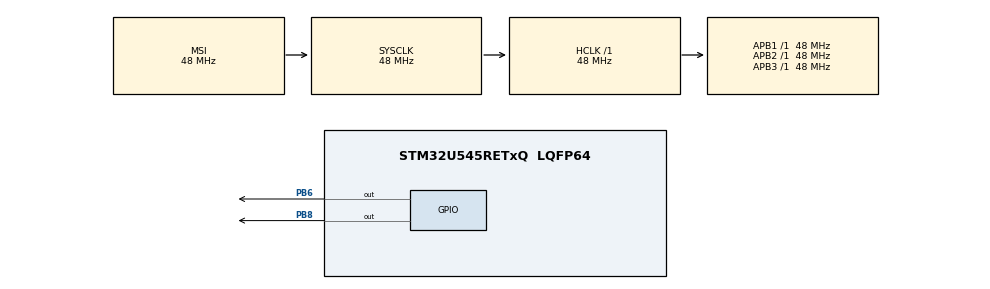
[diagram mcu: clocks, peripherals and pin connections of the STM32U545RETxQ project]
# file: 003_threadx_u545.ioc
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CORTEX_M33_NS.userName=CORTEX_M33
Mcu.Family=STM32U5
Mcu.Name=STM32U545RETxQ
Mcu.Package=LQFP64
NVIC.IWDG_IRQn=true\:0\:0\:false\:false\:true\:false\:true\:true\:true
NVIC.LPTIM1_IRQn=true\:0\:0\:false\:false\:true\:false\:true\:true\:true
NVIC.PriorityGroup=NVIC_PRIORITYGROUP_4
NVIC.RTC_IRQn=true\:0\:0\:false\:false\:true\:false\:true\:true\:true
NVIC.TIM1_UP_IRQn=true\:15\:0\:false\:false\:true\:false\:false\:true\:true
NVIC.TIM4_IRQn=true\:0\:0\:false\:false\:true\:false\:true\:true\:true
NVIC.TimeBase=TIM1_UP_IRQn
NVIC.TimeBaseIP=TIM1
PB6.Signal=GPIO_Output
PB8.Signal=GPIO_Output
PC14-OSC32_IN\ (PC14).Mode=LSE-External-Oscillator
PC14-OSC32_IN\ (PC14).Signal=RCC_OSC32_IN
PC15-OSC32_OUT\ (PC15).Mode=LSE-External-Oscillator
PC15-OSC32_OUT\ (PC15).Signal=RCC_OSC32_OUT
PWR.PowerMode=PWR_SMPS_SUPPLY
ProjectManager.HeapSize=0x200
ProjectManager.StackSize=0x400
ProjectManager.TargetToolchain=STM32CubeIDE
RCC.ADCFreq_Value=16000000
RCC.AHBFreq_Value=48000000
RCC.APB1Freq_Value=48000000
RCC.APB1TimFreq_Value=48000000
RCC.APB2Freq_Value=48000000
RCC.APB2TimFreq_Value=48000000
RCC.APB3Freq_Value=48000000
RCC.CortexFreq_Value=48000000
RCC.DACCLockSelectionVirtualString=RCC_DAC1CLKSOURCE_LSI
RCC.EPOD_VALUE=48000000
RCC.HCLKFreq_Value=48000000
RCC.HSE_VALUE=16000000
RCC.HSI48_VALUE=48000000
RCC.HSI_VALUE=16000000
RCC.LSIDIV_VALUE=32000
RCC.MSIClockRange=RCC_MSIRANGE_0
RCC.MSI_VALUE=48000000
RCC.SYSCLKFreq_VALUE=48000000
RCC.USBFreq_Value=48000000
RCC.VCOOutputFreq_Value=6192000000
THREADX.TX_APP_CREATION=1
THREADX.TX_APP_GENERATE_INIT_CODE=true
THREADX.TX_APP_MEM_POOL_SIZE=8192
THREADX.TX_APP_MSG_QUEUE_CREATION=1
THREADX.TX_APP_MUTEX_CREATION=1
THREADX.TX_APP_SEM_CREATION=1
THREADX.TX_APP_STACK_SIZE=4096
THREADX.TX_LOW_POWER=1
THREADX.TX_MINIMUM_STACK=200
THREADX.TX_TIMER_THREAD_STACK_SIZE=4096
VP_ICACHE_VS_ICACHE.Mode=DirectMappedCache
VP_IWDG_VS_IWDG.Mode=IWDG_Activate
VP_LPBAMQUEUE_VS_QUEUE.Mode=QUEUEMODE
VP_LPBAM_VS_SIG1.Mode=SmartRun
VP_LPBAM_VS_SIG4.Mode=LPDMA1
VP_LPTIM1_VS_LPTIM_counterModeInternalClock.Mode=Counts__internal_clock_event_00
VP_MEMORYMAP_VS_MEMORYMAP.Mode=CurAppReg
VP_PWR_VS_LPOM.Mode=PowerOptimisation
VP_PWR_VS_SECSignals.Mode=Security/Privilege
VP_RTC_VS_RTC_Activate.Mode=RTC_Enabled
VP_RTC_VS_RTC_Calendar.Mode=RTC_Calendar
VP_RTC_VS_RTC_WakeUp_intern.Mode=WakeUp
VP_SYS_VS_tim1.Mode=TIM1
VP_THREADX_VS_RTOSJjThreadXJjCoreJjDefault.Mode=Core_Default
VP_THREADX_VS_RTOSJjThreadXJjLow_Power_Support.Mode=Low_Power_Support
VP_THREADX_VS_RTOSJjThreadXJjPerformance_InfoJjDefault.Mode=Performance_Default
VP_TIM4_VS_ClockSourceINT.Mode=Internal
board=custom

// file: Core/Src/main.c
/* USER CODE BEGIN Header */
/**
  ******************************************************************************
  * @file           : main.c
  * @brief          : Main program body
  ******************************************************************************
  * @attention
  *
  * Copyright (c) 2025 STMicroelectronics.
  * All rights reserved.
  *
  * This software is licensed under terms that can be found in the LICENSE file
  * in the root directory of this software component.
  * If no LICENSE file comes with this software, it is provided AS-IS.
  *
  ******************************************************************************
  */
/* USER CODE END Header */
#include "app_threadx.h"
#include "main.h"
#include "icache.h"
#include "iwdg.h"
#include "lptim.h"
#include "rtc.h"
#include "tim.h"
#include "gpio.h"

/* USER CODE BEGIN Includes */
#include "SEGGER_RTT.h"
/* USER CODE END Includes */

void SystemClock_Config(void);
static void SystemPower_Config(void);

int main(void)
{

  /* USER CODE BEGIN 1 */
  /* Initialize RTT early for debugging */
  SEGGER_RTT_Init();
  SEGGER_RTT_printf(0, "\r\n=== STM32U545 ThreadX Application Starting ===\r\n");
  SEGGER_RTT_printf(0, "Build Date: %s %s\r\n", __DATE__, __TIME__);
  SEGGER_RTT_printf(0, "MCU: STM32U545RETXQ\r\n");
  SEGGER_RTT_printf(0, "RTOS: ThreadX\r\n");
  SEGGER_RTT_printf(0, "===============================================\r\n");
  /* USER CODE END 1 */

  /* MCU Configuration--------------------------------------------------------*/

  /* Reset of all peripherals, Initializes the Flash interface and the Systick. */
  HAL_Init();

  /* USER CODE BEGIN Init */
  SEGGER_RTT_printf(0, "HAL_Init() completed\r\n");
  /* USER CODE END Init */

  /* Configure the System Power */
  SystemPower_Config();

  /* Configure the system clock */
  SystemClock_Config();

  /* USER CODE BEGIN SysInit */
  SEGGER_RTT_printf(0, "System Power and Clock configuration completed\r\n");
  SEGGER_RTT_printf(0, "System Clock: %lu Hz\r\n", HAL_RCC_GetSysClockFreq());
  SEGGER_RTT_printf(0, "HCLK: %lu Hz\r\n", HAL_RCC_GetHCLKFreq());
  SEGGER_RTT_printf(0, "PCLK1: %lu Hz\r\n", HAL_RCC_GetPCLK1Freq());
  SEGGER_RTT_printf(0, "PCLK2: %lu Hz\r\n", HAL_RCC_GetPCLK2Freq());
  SEGGER_RTT_printf(0, "PCLK3: %lu Hz\r\n", HAL_RCC_GetPCLK3Freq());
  /* USER CODE END SysInit */

  /* Initialize all configured peripherals */
  MX_GPIO_Init();
  MX_ICACHE_Init();
  MX_IWDG_Init();
  MX_LPTIM1_Init();
  MX_RTC_Init();
  MX_TIM4_Init();
  /* USER CODE BEGIN 2 */
  SEGGER_RTT_printf(0, "All peripherals initialized successfully\r\n");
  SEGGER_RTT_printf(0, "Starting ThreadX RTOS...\r\n");
  /* USER CODE END 2 */

  MX_ThreadX_Init();

  /* We should never get here as control is now taken by the scheduler */

  /* Infinite loop */
  while (1)
  {

    /* USER CODE BEGIN 3 */
    /* This should never be reached as ThreadX takes control */
    SEGGER_RTT_printf(0, "ERROR: Unexpected return to main loop!\r\n");
    HAL_Delay(1000);
  }
  /* USER CODE END 3 */
}

void SystemClock_Config(void)
{
  RCC_OscInitTypeDef RCC_OscInitStruct = {0};
  RCC_ClkInitTypeDef RCC_ClkInitStruct = {0};

  /** Configure the main internal regulator output voltage
  */
  if (HAL_PWREx_ControlVoltageScaling(PWR_REGULATOR_VOLTAGE_SCALE3) != HAL_OK)
  {
    Error_Handler();
  }

  /** Initializes the CPU, AHB and APB buses clocks
  */
  RCC_OscInitStruct.OscillatorType = RCC_OSCILLATORTYPE_LSI|RCC_OSCILLATORTYPE_MSI
                              |RCC_OSCILLATORTYPE_MSIK;
  RCC_OscInitStruct.LSIState = RCC_LSI_ON;
  RCC_OscInitStruct.MSIState = RCC_MSI_ON;
  RCC_OscInitStruct.MSICalibrationValue = RCC_MSICALIBRATION_DEFAULT;
  RCC_OscInitStruct.MSIClockRange = RCC_MSIRANGE_0;
  RCC_OscInitStruct.LSIDiv = RCC_LSI_DIV1;
  RCC_OscInitStruct.MSIKClockRange = RCC_MSIKRANGE_4;
  RCC_OscInitStruct.MSIKState = RCC_MSIK_ON;
  RCC_OscInitStruct.PLL.PLLState = RCC_PLL_NONE;
  if (HAL_RCC_OscConfig(&RCC_OscInitStruct) != HAL_OK)
  {
    Error_Handler();
  }

  /** Initializes the CPU, AHB and APB buses clocks
  */
  RCC_ClkInitStruct.ClockType = RCC_CLOCKTYPE_HCLK|RCC_CLOCKTYPE_SYSCLK
                              |RCC_CLOCKTYPE_PCLK1|RCC_CLOCKTYPE_PCLK2
                              |RCC_CLOCKTYPE_PCLK3;
  RCC_ClkInitStruct.SYSCLKSource = RCC_SYSCLKSOURCE_MSI;
  RCC_ClkInitStruct.AHBCLKDivider = RCC_SYSCLK_DIV1;
  RCC_ClkInitStruct.APB1CLKDivider = RCC_HCLK_DIV1;
  RCC_ClkInitStruct.APB2CLKDivider = RCC_HCLK_DIV1;
  RCC_ClkInitStruct.APB3CLKDivider = RCC_HCLK_DIV1;

  if (HAL_RCC_ClockConfig(&RCC_ClkInitStruct, FLASH_LATENCY_1) != HAL_OK)
  {
    Error_Handler();
  }

  /** Enable the force of MSIK in stop mode
  */
  __HAL_RCC_MSIKSTOP_ENABLE();
}

/**
  * @brief Power Configuration
  * @retval None
  */
static void SystemPower_Config(void)
{

  /*
   * Switch to SMPS regulator instead of LDO
   */
  if (HAL_PWREx_ConfigSupply(PWR_SMPS_SUPPLY) != HAL_OK)
  {
    Error_Handler();
  }
}

void HAL_TIM_PeriodElapsedCallback(TIM_HandleTypeDef *htim)
{
  if (htim->Instance == TIM1)
  {
    HAL_IncTick();
  }
}

void Error_Handler(void)
{
  __disable_irq();
  while (1)
  {
  }
}
